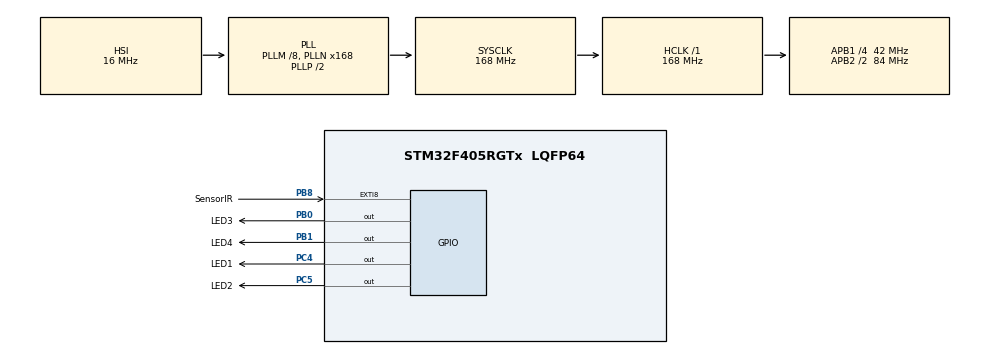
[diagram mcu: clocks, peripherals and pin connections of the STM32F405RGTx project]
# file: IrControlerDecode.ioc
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Mcu.Family=STM32F4
Mcu.Name=STM32F405RGTx
Mcu.Package=LQFP64
NVIC.EXTI9_5_IRQn=true\:0\:0\:false\:false\:true\:true\:true\:true
NVIC.PriorityGroup=NVIC_PRIORITYGROUP_4
NVIC.TIM1_BRK_TIM9_IRQn=true\:0\:0\:false\:false\:true\:true\:true\:true
NVIC.TIM1_CC_IRQn=true\:0\:0\:false\:false\:true\:true\:true\:true
NVIC.TIM1_TRG_COM_TIM11_IRQn=true\:0\:0\:false\:false\:true\:true\:true\:true
NVIC.TIM1_UP_TIM10_IRQn=true\:0\:0\:false\:false\:true\:true\:true\:true
PB0.GPIO_Label=LED3
PB0.Signal=GPIO_Output
PB1.GPIO_Label=LED4
PB1.Signal=GPIO_Output
PB8.GPIO_Label=SensorIR
PB8.GPIO_ModeDefaultEXTI=GPIO_MODE_IT_FALLING
PB8.Signal=GPXTI8
PC4.GPIO_Label=LED1
PC4.Signal=GPIO_Output
PC5.GPIO_Label=LED2
PC5.Signal=GPIO_Output
ProjectManager.HeapSize=0x200
ProjectManager.StackSize=0x400
ProjectManager.TargetToolchain=STM32CubeIDE
RCC.48MHZClocksFreq_Value=84000000
RCC.AHBFreq_Value=168000000
RCC.APB1CLKDivider=RCC_HCLK_DIV4
RCC.APB1Freq_Value=42000000
RCC.APB1TimFreq_Value=84000000
RCC.APB2CLKDivider=RCC_HCLK_DIV2
RCC.APB2Freq_Value=84000000
RCC.APB2TimFreq_Value=168000000
RCC.CortexFreq_Value=168000000
RCC.HCLKFreq_Value=168000000
RCC.HSE_VALUE=25000000
RCC.HSI_VALUE=16000000
RCC.LSE_VALUE=32768
RCC.PLLM=8
RCC.PLLN=168
RCC.SYSCLKFreq_VALUE=168000000
RCC.SYSCLKSource=RCC_SYSCLKSOURCE_PLLCLK
RCC.VCOOutputFreq_Value=336000000
TIM1.Period=65535
TIM1.TIM_MasterSlaveMode=TIM_MASTERSLAVEMODE_ENABLE
VP_TIM1_VS_ClockSourceINT.Mode=Internal
board=custom

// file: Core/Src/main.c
/* USER CODE BEGIN Header */
/**
  ******************************************************************************
  * @file           : main.c
  * @brief          : Main program body
  ******************************************************************************
  * @attention
  *
  * Copyright (c) 2022 STMicroelectronics.
  * All rights reserved.
  *
  * This software is licensed under terms that can be found in the LICENSE file
  * in the root directory of this software component.
  * If no LICENSE file comes with this software, it is provided AS-IS.
  *
  ******************************************************************************
  */
/* USER CODE END Header */
#include "main.h"

/* USER CODE BEGIN Includes */
#include "micros.h"
/* USER CODE END Includes */

 TIM_HandleTypeDef htim1;

void SystemClock_Config(void);
static void MX_GPIO_Init(void);
static void MX_TIM1_Init(void);

/* USER CODE BEGIN 0 */
uint16_t microsecondsTime;
int inicial;
int interrup;
int valordopino;

void HAL_GPIO_EXTI_Callback(uint16_t GPIO_Pin) {
	if(GPIO_Pin == SensorIR_Pin) {
	   Interruption();
	}
}

/* USER CODE END 0 */

int main(void)
{

  /* MCU Configuration--------------------------------------------------------*/

  /* Reset of all peripherals, Initializes the Flash interface and the Systick. */
  HAL_Init();

  /* Configure the system clock */
  SystemClock_Config();

  /* Initialize all configured peripherals */
  MX_GPIO_Init();
  MX_TIM1_Init();
  /* USER CODE BEGIN 2 */
  DWT_Init();
  /* USER CODE END 2 */

  /* Infinite loop */
  while (1)
  {

    /* USER CODE BEGIN 3 */
	  interrup++;
	  valordopino = HAL_GPIO_ReadPin(SensorIR_GPIO_Port, SensorIR_Pin);
	  mainCpp();

  }
  /* USER CODE END 3 */
}

void SystemClock_Config(void)
{
  RCC_OscInitTypeDef RCC_OscInitStruct = {0};
  RCC_ClkInitTypeDef RCC_ClkInitStruct = {0};

  /** Configure the main internal regulator output voltage
  */
  __HAL_RCC_PWR_CLK_ENABLE();
  __HAL_PWR_VOLTAGESCALING_CONFIG(PWR_REGULATOR_VOLTAGE_SCALE1);

  /** Initializes the RCC Oscillators according to the specified parameters
  * in the RCC_OscInitTypeDef structure.
  */
  RCC_OscInitStruct.OscillatorType = RCC_OSCILLATORTYPE_HSI;
  RCC_OscInitStruct.HSIState = RCC_HSI_ON;
  RCC_OscInitStruct.HSICalibrationValue = RCC_HSICALIBRATION_DEFAULT;
  RCC_OscInitStruct.PLL.PLLState = RCC_PLL_ON;
  RCC_OscInitStruct.PLL.PLLSource = RCC_PLLSOURCE_HSI;
  RCC_OscInitStruct.PLL.PLLM = 8;
  RCC_OscInitStruct.PLL.PLLN = 168;
  RCC_OscInitStruct.PLL.PLLP = RCC_PLLP_DIV2;
  RCC_OscInitStruct.PLL.PLLQ = 4;
  if (HAL_RCC_OscConfig(&RCC_OscInitStruct) != HAL_OK)
  {
    Error_Handler();
  }

  /** Initializes the CPU, AHB and APB buses clocks
  */
  RCC_ClkInitStruct.ClockType = RCC_CLOCKTYPE_HCLK|RCC_CLOCKTYPE_SYSCLK
                              |RCC_CLOCKTYPE_PCLK1|RCC_CLOCKTYPE_PCLK2;
  RCC_ClkInitStruct.SYSCLKSource = RCC_SYSCLKSOURCE_PLLCLK;
  RCC_ClkInitStruct.AHBCLKDivider = RCC_SYSCLK_DIV1;
  RCC_ClkInitStruct.APB1CLKDivider = RCC_HCLK_DIV4;
  RCC_ClkInitStruct.APB2CLKDivider = RCC_HCLK_DIV2;

  if (HAL_RCC_ClockConfig(&RCC_ClkInitStruct, FLASH_LATENCY_5) != HAL_OK)
  {
    Error_Handler();
  }
}

static void MX_TIM1_Init(void)
{

  TIM_ClockConfigTypeDef sClockSourceConfig = {0};
  TIM_MasterConfigTypeDef sMasterConfig = {0};

  htim1.Instance = TIM1;
  htim1.Init.Prescaler = 0;
  htim1.Init.CounterMode = TIM_COUNTERMODE_UP;
  htim1.Init.Period = 65535;
  htim1.Init.ClockDivision = TIM_CLOCKDIVISION_DIV1;
  htim1.Init.RepetitionCounter = 0;
  htim1.Init.AutoReloadPreload = TIM_AUTORELOAD_PRELOAD_DISABLE;
  if (HAL_TIM_Base_Init(&htim1) != HAL_OK)
  {
    Error_Handler();
  }
  sClockSourceConfig.ClockSource = TIM_CLOCKSOURCE_INTERNAL;
  if (HAL_TIM_ConfigClockSource(&htim1, &sClockSourceConfig) != HAL_OK)
  {
    Error_Handler();
  }
  sMasterConfig.MasterOutputTrigger = TIM_TRGO_RESET;
  sMasterConfig.MasterSlaveMode = TIM_MASTERSLAVEMODE_ENABLE;
  if (HAL_TIMEx_MasterConfigSynchronization(&htim1, &sMasterConfig) != HAL_OK)
  {
    Error_Handler();
  }

}

static void MX_GPIO_Init(void)
{
  GPIO_InitTypeDef GPIO_InitStruct = {0};

  /* GPIO Ports Clock Enable */
  __HAL_RCC_GPIOC_CLK_ENABLE();
  __HAL_RCC_GPIOB_CLK_ENABLE();

  /*Configure GPIO pin Output Level */
  HAL_GPIO_WritePin(GPIOC, LED1_Pin|LED2_Pin, GPIO_PIN_RESET);

  /*Configure GPIO pin Output Level */
  HAL_GPIO_WritePin(GPIOB, LED3_Pin|LED4_Pin, GPIO_PIN_RESET);

  /*Configure GPIO pins : LED1_Pin LED2_Pin */
  GPIO_InitStruct.Pin = LED1_Pin|LED2_Pin;
  GPIO_InitStruct.Mode = GPIO_MODE_OUTPUT_PP;
  GPIO_InitStruct.Pull = GPIO_NOPULL;
  GPIO_InitStruct.Speed = GPIO_SPEED_FREQ_LOW;
  HAL_GPIO_Init(GPIOC, &GPIO_InitStruct);

  /*Configure GPIO pins : LED3_Pin LED4_Pin */
  GPIO_InitStruct.Pin = LED3_Pin|LED4_Pin;
  GPIO_InitStruct.Mode = GPIO_MODE_OUTPUT_PP;
  GPIO_InitStruct.Pull = GPIO_NOPULL;
  GPIO_InitStruct.Speed = GPIO_SPEED_FREQ_LOW;
  HAL_GPIO_Init(GPIOB, &GPIO_InitStruct);

  /*Configure GPIO pin : SensorIR_Pin */
  GPIO_InitStruct.Pin = SensorIR_Pin;
  GPIO_InitStruct.Mode = GPIO_MODE_IT_FALLING;
  GPIO_InitStruct.Pull = GPIO_NOPULL;
  HAL_GPIO_Init(SensorIR_GPIO_Port, &GPIO_InitStruct);

  /* EXTI interrupt init*/
  HAL_NVIC_SetPriority(EXTI9_5_IRQn, 0, 0);
  HAL_NVIC_EnableIRQ(EXTI9_5_IRQn);

}

void Error_Handler(void)
{
  __disable_irq();
  while (1)
  {
  }
}
